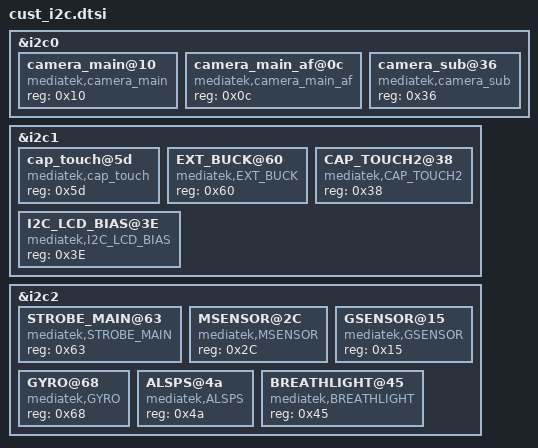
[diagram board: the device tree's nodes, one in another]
/*
 * Generated by MTK SP Drv_CodeGen Version 03.13.6  for MT6735. Copyright MediaTek Inc. (C) 2013.
 * Thu Jun  4 21:49:55 2015
 * Do Not Modify the File.
 */

/*************************
 * I2C dtsi file
*************************/

&i2c0 {
	camera_main@10 {
		compatible = "mediatek,camera_main";
		reg = <0x10>;
	};

	camera_main_af@0c {
		compatible = "mediatek,camera_main_af";
		reg = <0x0c>;
	};

	camera_sub@36 {
		compatible = "mediatek,camera_sub";
		reg = <0x36>;
	};

};

&i2c1 {
	cap_touch@5d {
		compatible = "mediatek,cap_touch";
		reg = <0x5d>;
	};

	EXT_BUCK@60 {
		compatible = "mediatek,EXT_BUCK";
		reg = <0x60>;
	};

	CAP_TOUCH2@38 {
		compatible = "mediatek,CAP_TOUCH2";
		reg = <0x38>;
	};

	I2C_LCD_BIAS@3E {
		compatible = "mediatek,I2C_LCD_BIAS";
		reg = <0x3E>;
	};

};

&i2c2 {
	STROBE_MAIN@63 {
		compatible = "mediatek,STROBE_MAIN";
		reg = <0x63>;
	};

	MSENSOR@2C {
		compatible = "mediatek,MSENSOR";
		reg = <0x2C>;
	};

	GSENSOR@15 {
		compatible = "mediatek,GSENSOR";
		reg = <0x15>;
	};

	GYRO@68 {
		compatible = "mediatek,GYRO";
		reg = <0x68>;
	};

	ALSPS@4a {
		compatible = "mediatek,ALSPS";
		reg = <0x4a>;
	};

	BREATHLIGHT@45 {
		compatible = "mediatek,BREATHLIGHT";
		reg = <0x45>;
	};
};
